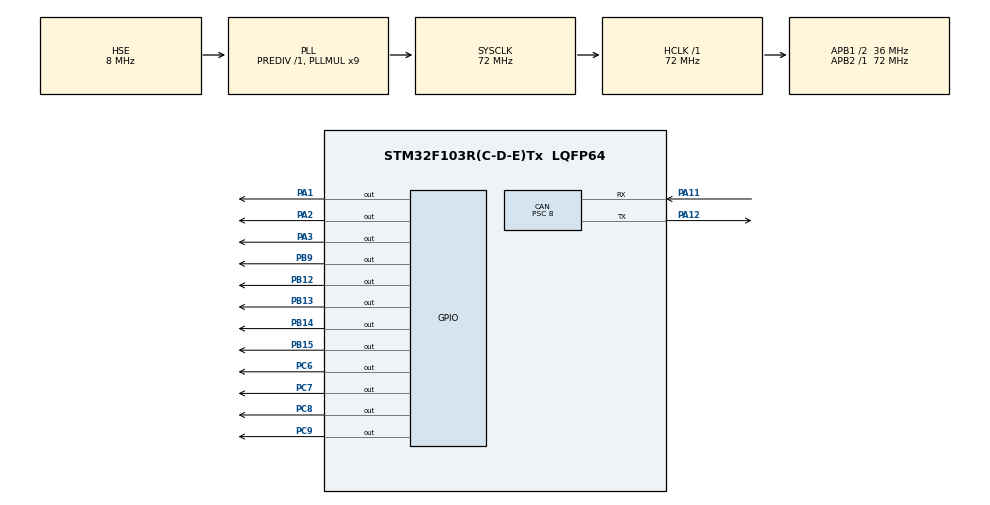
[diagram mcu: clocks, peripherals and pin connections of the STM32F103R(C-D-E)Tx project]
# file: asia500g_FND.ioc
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CAN.ABOM=ENABLE
CAN.BS1=CAN_BS1_3TQ
CAN.BS2=CAN_BS2_5TQ
CAN.CalculateBaudRate=500000
CAN.CalculateTimeBit=2000
CAN.CalculateTimeQuantum=222.22222222222223
CAN.NART=ENABLE
CAN.Prescaler=8
Mcu.Family=STM32F1
Mcu.Name=STM32F103R(C-D-E)Tx
Mcu.Package=LQFP64
NVIC.CAN1_RX1_IRQn=true\:0\:0\:false\:false\:true\:true\:true\:true
NVIC.CAN1_SCE_IRQn=true\:0\:0\:false\:false\:true\:true\:true\:true
NVIC.PriorityGroup=NVIC_PRIORITYGROUP_4
NVIC.TIM2_IRQn=true\:0\:0\:false\:false\:true\:true\:true\:true
NVIC.USB_HP_CAN1_TX_IRQn=true\:0\:0\:false\:false\:true\:true\:true\:true
NVIC.USB_LP_CAN1_RX0_IRQn=true\:0\:0\:false\:false\:true\:true\:true\:true
PA1.GPIO_PuPd=GPIO_PULLDOWN
PA1.Signal=GPIO_Output
PA11.Mode=CAN_Activate
PA11.Signal=CAN_RX
PA12.Mode=CAN_Activate
PA12.Signal=CAN_TX
PA13.Mode=Serial_Wire
PA13.Signal=SYS_JTMS-SWDIO
PA14.Mode=Serial_Wire
PA14.Signal=SYS_JTCK-SWCLK
PA2.GPIO_PuPd=GPIO_PULLDOWN
PA2.Signal=GPIO_Output
PA3.GPIO_PuPd=GPIO_PULLDOWN
PA3.Signal=GPIO_Output
PB12.GPIO_PuPd=GPIO_PULLUP
PB12.Signal=GPIO_Output
PB13.GPIO_PuPd=GPIO_PULLUP
PB13.Signal=GPIO_Output
PB14.GPIO_PuPd=GPIO_PULLUP
PB14.Signal=GPIO_Output
PB15.GPIO_PuPd=GPIO_PULLUP
PB15.Signal=GPIO_Output
PB9.GPIO_PuPd=GPIO_PULLUP
PB9.Signal=GPIO_Output
PC6.GPIO_PuPd=GPIO_PULLUP
PC6.Signal=GPIO_Output
PC7.GPIO_PuPd=GPIO_PULLUP
PC7.Signal=GPIO_Output
PC8.GPIO_PuPd=GPIO_PULLUP
PC8.Signal=GPIO_Output
PC9.GPIO_PuPd=GPIO_PULLUP
PC9.Signal=GPIO_Output
PD0-OSC_IN.Mode=HSE-External-Oscillator
PD0-OSC_IN.Signal=RCC_OSC_IN
PD1-OSC_OUT.Mode=HSE-External-Oscillator
PD1-OSC_OUT.Signal=RCC_OSC_OUT
ProjectManager.HeapSize=0x200
ProjectManager.StackSize=0x400
ProjectManager.TargetToolchain=STM32CubeIDE
RCC.AHBFreq_Value=72000000
RCC.APB1CLKDivider=RCC_HCLK_DIV2
RCC.APB1Freq_Value=36000000
RCC.APB1TimFreq_Value=72000000
RCC.APB2Freq_Value=72000000
RCC.APB2TimFreq_Value=72000000
RCC.HCLKFreq_Value=72000000
RCC.PLLMUL=RCC_PLL_MUL9
RCC.PLLSourceVirtual=RCC_PLLSOURCE_HSE
RCC.SYSCLKFreq_VALUE=72000000
RCC.SYSCLKSource=RCC_SYSCLKSOURCE_PLLCLK
RCC.USBFreq_Value=72000000
TIM2.CounterMode=TIM_COUNTERMODE_UP
TIM2.Period=100-1
TIM2.Prescaler=720-1
VP_TIM2_VS_ClockSourceINT.Mode=Internal
board=custom

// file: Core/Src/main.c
/* USER CODE BEGIN Header */
/**
  ******************************************************************************
  * @file           : main.c
  * @brief          : Main program body
  ******************************************************************************
  * @attention
  *
  * Copyright (c) 2024 STMicroelectronics.
  * All rights reserved.
  *
  * This software is licensed under terms that can be found in the LICENSE file
  * in the root directory of this software component.
  * If no LICENSE file comes with this software, it is provided AS-IS.
  *
  ******************************************************************************
  */
/* USER CODE END Header */
#include "main.h"
#include "can.h"
#include "tim.h"
#include "gpio.h"

/* USER CODE BEGIN Includes */
#include "7segment.h"
#include "task.h"
#include "bsp_can.h"
/* USER CODE END Includes */

void SystemClock_Config(void);

int main(void)
{

  /* MCU Configuration--------------------------------------------------------*/

  /* Reset of all peripherals, Initializes the Flash interface and the Systick. */
  HAL_Init();

  /* Configure the system clock */
  SystemClock_Config();

  /* Initialize all configured peripherals */
  MX_GPIO_Init();
  MX_CAN_Init();
  MX_TIM2_Init();
  /* USER CODE BEGIN 2 */
  HAL_TIM_Base_Start_IT (&htim2); // 1ms
  bsp_can_init();
  /* USER CODE END 2 */

  /* Infinite loop */
  while (1)
  {
    Timer_Event();

    #if 1
    can_data_decoder();
    Error_code_dispay();
    #endif
  }
}

void SystemClock_Config(void)
{
  RCC_OscInitTypeDef RCC_OscInitStruct = {0};
  RCC_ClkInitTypeDef RCC_ClkInitStruct = {0};

  /** Initializes the RCC Oscillators according to the specified parameters
  * in the RCC_OscInitTypeDef structure.
  */
  RCC_OscInitStruct.OscillatorType = RCC_OSCILLATORTYPE_HSE;
  RCC_OscInitStruct.HSEState = RCC_HSE_ON;
  RCC_OscInitStruct.HSEPredivValue = RCC_HSE_PREDIV_DIV1;
  RCC_OscInitStruct.HSIState = RCC_HSI_ON;
  RCC_OscInitStruct.PLL.PLLState = RCC_PLL_ON;
  RCC_OscInitStruct.PLL.PLLSource = RCC_PLLSOURCE_HSE;
  RCC_OscInitStruct.PLL.PLLMUL = RCC_PLL_MUL9;
  if (HAL_RCC_OscConfig(&RCC_OscInitStruct) != HAL_OK)
  {
    Error_Handler();
  }

  /** Initializes the CPU, AHB and APB buses clocks
  */
  RCC_ClkInitStruct.ClockType = RCC_CLOCKTYPE_HCLK|RCC_CLOCKTYPE_SYSCLK
                              |RCC_CLOCKTYPE_PCLK1|RCC_CLOCKTYPE_PCLK2;
  RCC_ClkInitStruct.SYSCLKSource = RCC_SYSCLKSOURCE_PLLCLK;
  RCC_ClkInitStruct.AHBCLKDivider = RCC_SYSCLK_DIV1;
  RCC_ClkInitStruct.APB1CLKDivider = RCC_HCLK_DIV2;
  RCC_ClkInitStruct.APB2CLKDivider = RCC_HCLK_DIV1;

  if (HAL_RCC_ClockConfig(&RCC_ClkInitStruct, FLASH_LATENCY_2) != HAL_OK)
  {
    Error_Handler();
  }
}

void Error_Handler(void)
{
  __disable_irq();
  while (1)
  {
  }
}
